AUTOSAR XML (schema 4-2-2)
package /COM_SWC
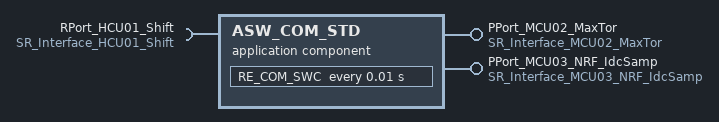
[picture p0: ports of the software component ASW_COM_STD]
  application sw component type ASW_COM_STD
    provide port PPort_MCU02_MaxTor: provided-interface=SR_Interface_MCU02_MaxTor
    provide port PPort_MCU03_NRF_IdcSamp: provided-interface=SR_Interface_MCU03_NRF_IdcSamp
    require port RPort_HCU01_Shift: nonqueued-receiver-com-spec{alive-timeout=0.3, data-element=HCU01_Shift}, required-interface=SR_Interface_HCU01_Shift
    behavior IB_ASW_COM_STD
      timing event TE_RE_COM_SWC: start-on-event=RE_COM_SWC, period=0.01
      runnable RE_COM_SWC
        data-receive-point-by-arguments:
          access REC_RPort_HCU01_Shift_HCU01_Shift: accessed-variable=RPort_HCU01_Shift.HCU01_Shift
        data-send-points:
          access SEND_PPort_MCU02_MaxTor_MCU02_MaxTor: accessed-variable=PPort_MCU02_MaxTor.MCU02_MaxTor
          access SEND_PPort_MCU03_NRF_IdcSamp_MCU03_NRF_IdcSamp: accessed-variable=PPort_MCU03_NRF_IdcSamp.MCU03_NRF_IdcSamp
